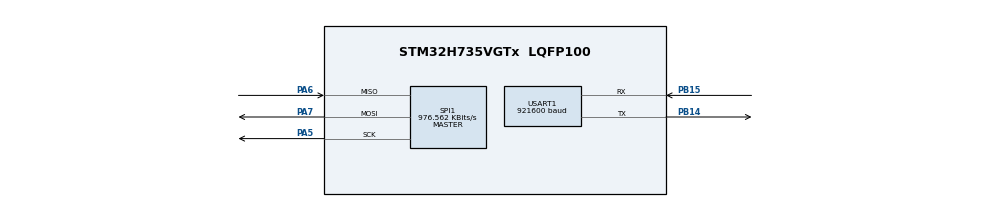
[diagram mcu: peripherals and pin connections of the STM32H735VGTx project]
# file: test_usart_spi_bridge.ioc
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CORTEX_M7.default_mode_Activation=1
Dma.Request0=USART1_RX
Dma.Request1=SPI1_RX
Dma.Request2=SPI1_TX
Dma.Request3=USART1_TX
Dma.SPI1_RX.1.Direction=DMA_PERIPH_TO_MEMORY
Dma.SPI1_RX.1.EventEnable=DISABLE
Dma.SPI1_RX.1.FIFOMode=DMA_FIFOMODE_DISABLE
Dma.SPI1_RX.1.Instance=DMA1_Stream3
Dma.SPI1_RX.1.MemDataAlignment=DMA_MDATAALIGN_BYTE
Dma.SPI1_RX.1.MemInc=DMA_MINC_ENABLE
Dma.SPI1_RX.1.Mode=DMA_CIRCULAR
Dma.SPI1_RX.1.PeriphDataAlignment=DMA_PDATAALIGN_BYTE
Dma.SPI1_RX.1.PeriphInc=DMA_PINC_DISABLE
Dma.SPI1_RX.1.Polarity=HAL_DMAMUX_REQ_GEN_RISING
Dma.SPI1_RX.1.Priority=DMA_PRIORITY_LOW
Dma.SPI1_RX.1.RequestNumber=1
Dma.SPI1_RX.1.SignalID=NONE
Dma.SPI1_RX.1.SyncEnable=DISABLE
Dma.SPI1_RX.1.SyncPolarity=HAL_DMAMUX_SYNC_NO_EVENT
Dma.SPI1_RX.1.SyncRequestNumber=1
Dma.SPI1_RX.1.SyncSignalID=NONE
Dma.SPI1_TX.2.Direction=DMA_MEMORY_TO_PERIPH
Dma.SPI1_TX.2.EventEnable=DISABLE
Dma.SPI1_TX.2.FIFOMode=DMA_FIFOMODE_DISABLE
Dma.SPI1_TX.2.Instance=DMA1_Stream2
Dma.SPI1_TX.2.MemDataAlignment=DMA_MDATAALIGN_BYTE
Dma.SPI1_TX.2.MemInc=DMA_MINC_ENABLE
Dma.SPI1_TX.2.Mode=DMA_NORMAL
Dma.SPI1_TX.2.PeriphDataAlignment=DMA_PDATAALIGN_BYTE
Dma.SPI1_TX.2.PeriphInc=DMA_PINC_DISABLE
Dma.SPI1_TX.2.Polarity=HAL_DMAMUX_REQ_GEN_RISING
Dma.SPI1_TX.2.Priority=DMA_PRIORITY_LOW
Dma.SPI1_TX.2.RequestNumber=1
Dma.SPI1_TX.2.SignalID=NONE
Dma.SPI1_TX.2.SyncEnable=DISABLE
Dma.SPI1_TX.2.SyncPolarity=HAL_DMAMUX_SYNC_NO_EVENT
Dma.SPI1_TX.2.SyncRequestNumber=1
Dma.SPI1_TX.2.SyncSignalID=NONE
Dma.USART1_RX.0.Direction=DMA_PERIPH_TO_MEMORY
Dma.USART1_RX.0.EventEnable=DISABLE
Dma.USART1_RX.0.FIFOMode=DMA_FIFOMODE_DISABLE
Dma.USART1_RX.0.Instance=DMA1_Stream0
Dma.USART1_RX.0.MemDataAlignment=DMA_MDATAALIGN_BYTE
Dma.USART1_RX.0.MemInc=DMA_MINC_ENABLE
Dma.USART1_RX.0.Mode=DMA_CIRCULAR
Dma.USART1_RX.0.PeriphDataAlignment=DMA_PDATAALIGN_BYTE
Dma.USART1_RX.0.PeriphInc=DMA_PINC_DISABLE
Dma.USART1_RX.0.Polarity=HAL_DMAMUX_REQ_GEN_RISING
Dma.USART1_RX.0.Priority=DMA_PRIORITY_LOW
Dma.USART1_RX.0.RequestNumber=1
Dma.USART1_RX.0.SignalID=NONE
Dma.USART1_RX.0.SyncEnable=DISABLE
Dma.USART1_RX.0.SyncPolarity=HAL_DMAMUX_SYNC_NO_EVENT
Dma.USART1_RX.0.SyncRequestNumber=1
Dma.USART1_RX.0.SyncSignalID=NONE
Dma.USART1_TX.3.Direction=DMA_MEMORY_TO_PERIPH
Dma.USART1_TX.3.EventEnable=DISABLE
Dma.USART1_TX.3.FIFOMode=DMA_FIFOMODE_DISABLE
Dma.USART1_TX.3.Instance=DMA1_Stream1
Dma.USART1_TX.3.MemDataAlignment=DMA_MDATAALIGN_BYTE
Dma.USART1_TX.3.MemInc=DMA_MINC_ENABLE
Dma.USART1_TX.3.Mode=DMA_NORMAL
Dma.USART1_TX.3.PeriphDataAlignment=DMA_PDATAALIGN_BYTE
Dma.USART1_TX.3.PeriphInc=DMA_PINC_DISABLE
Dma.USART1_TX.3.Polarity=HAL_DMAMUX_REQ_GEN_RISING
Dma.USART1_TX.3.Priority=DMA_PRIORITY_LOW
Dma.USART1_TX.3.RequestNumber=1
Dma.USART1_TX.3.SignalID=NONE
Dma.USART1_TX.3.SyncEnable=DISABLE
Dma.USART1_TX.3.SyncPolarity=HAL_DMAMUX_SYNC_NO_EVENT
Dma.USART1_TX.3.SyncRequestNumber=1
Dma.USART1_TX.3.SyncSignalID=NONE
FREERTOS.Tasks01=defaultTask,24,128,StartDefaultTask,Default,NULL,Dynamic,NULL,NULL
FREERTOS.configENABLE_BACKWARD_COMPATIBILITY=0
FREERTOS.configMAX_TASK_NAME_LEN=32
FREERTOS.configTOTAL_HEAP_SIZE=131072
FREERTOS.configUSE_NEWLIB_REENTRANT=1
Mcu.Family=STM32H7
Mcu.Name=STM32H735VGTx
Mcu.Package=LQFP100
NVIC.DMA1_Stream0_IRQn=true\:5\:0\:false\:false\:true\:true\:false\:true\:true
NVIC.DMA1_Stream1_IRQn=true\:5\:0\:true\:false\:true\:true\:false\:true\:true
NVIC.DMA1_Stream2_IRQn=true\:5\:0\:true\:false\:true\:true\:false\:true\:true
NVIC.DMA1_Stream3_IRQn=true\:5\:0\:true\:false\:true\:true\:false\:true\:true
NVIC.PriorityGroup=NVIC_PRIORITYGROUP_4
NVIC.SPI1_IRQn=true\:5\:0\:false\:false\:true\:true\:true\:true\:true
NVIC.TIM8_TRG_COM_TIM14_IRQn=true\:15\:0\:false\:false\:true\:false\:false\:true\:true
NVIC.TimeBase=TIM8_TRG_COM_TIM14_IRQn
NVIC.TimeBaseIP=TIM14
NVIC.USART1_IRQn=true\:5\:0\:false\:false\:true\:true\:true\:true\:true
PA13(JTMS/SWDIO).Mode=JTAG_4_pins
PA13(JTMS/SWDIO).Signal=DEBUG_JTMS-SWDIO
PA14(JTCK/SWCLK).Mode=JTAG_4_pins
PA14(JTCK/SWCLK).Signal=DEBUG_JTCK-SWCLK
PA15(JTDI).Mode=JTAG_4_pins
PA15(JTDI).Signal=DEBUG_JTDI
PA5.Mode=Full_Duplex_Master
PA5.Signal=SPI1_SCK
PA6.Mode=Full_Duplex_Master
PA6.Signal=SPI1_MISO
PA7.Mode=Full_Duplex_Master
PA7.Signal=SPI1_MOSI
PB14.Mode=Asynchronous
PB14.Signal=USART1_TX
PB15.Mode=Asynchronous
PB15.Signal=USART1_RX
PB3(JTDO/TRACESWO).Mode=JTAG_4_pins
PB3(JTDO/TRACESWO).Signal=DEBUG_JTDO-SWO
PH0-OSC_IN.Mode=HSE-External-Oscillator
PH0-OSC_IN.Signal=RCC_OSC_IN
PH1-OSC_OUT.Mode=HSE-External-Oscillator
PH1-OSC_OUT.Signal=RCC_OSC_OUT
ProjectManager.HeapSize=0x200
ProjectManager.StackSize=0x400
ProjectManager.TargetToolchain=STM32CubeIDE
RCC.ADCFreq_Value=250000000
RCC.APB1Freq_Value=125000000
RCC.APB2Freq_Value=125000000
RCC.APB3Freq_Value=125000000
RCC.APB4Freq_Value=125000000
RCC.CortexFreq_Value=500000000
RCC.D1PPRE=RCC_APB3_DIV2
RCC.D2PPRE1=RCC_APB1_DIV2
RCC.D2PPRE2=RCC_APB2_DIV2
RCC.D3PPRE=RCC_APB4_DIV2
RCC.DIVM1=5
RCC.DIVM2=5
RCC.DIVM3=5
RCC.DIVN1=100
RCC.DIVN2=100
RCC.DIVN3=100
RCC.DIVP1=1
RCC.DIVQ2=4
RCC.HCLKFreq_Value=250000000
RCC.HPRE=RCC_HCLK_DIV2
RCC.PLLSourceVirtual=RCC_PLLSOURCE_HSE
RCC.SPI123CLockSelection=RCC_SPI123CLKSOURCE_PLL2
RCC.SYSCLKFreq_VALUE=500000000
RCC.SYSCLKSource=RCC_SYSCLKSOURCE_PLLCLK
RCC.USART16CLockSelection=RCC_USART16910CLKSOURCE_PLL2
RCC.USBFreq_Value=250000000
SPI1.BaudRatePrescaler=SPI_BAUDRATEPRESCALER_256
SPI1.CalculateBaudRate=976.562 KBits/s
SPI1.DataSize=SPI_DATASIZE_8BIT
SPI1.Direction=SPI_DIRECTION_2LINES
SPI1.Mode=SPI_MODE_MASTER
SPI1.VirtualType=VM_MASTER
USART1.BaudRate=921600
USART1.VirtualMode-Asynchronous=VM_ASYNC
VP_FREERTOS_VS_CMSIS_V2.Mode=CMSIS_V2
VP_SYS_VS_tim14.Mode=TIM14
board=custom

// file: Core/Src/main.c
/* USER CODE BEGIN Header */
/**
  ******************************************************************************
  * @file           : main.c
  * @brief          : Main program body
  ******************************************************************************
  * @attention
  *
  * Copyright (c) 2024 STMicroelectronics.
  * All rights reserved.
  *
  * This software is licensed under terms that can be found in the LICENSE file
  * in the root directory of this software component.
  * If no LICENSE file comes with this software, it is provided AS-IS.
  *
  ******************************************************************************
  */
/* USER CODE END Header */
#include "main.h"
#include "cmsis_os.h"

/* USER CODE BEGIN Includes */
#include "bridge.h"
/* USER CODE END Includes */

SPI_HandleTypeDef hspi1;
DMA_HandleTypeDef hdma_spi1_rx;
DMA_HandleTypeDef hdma_spi1_tx;

UART_HandleTypeDef huart1;
DMA_HandleTypeDef hdma_usart1_rx;
DMA_HandleTypeDef hdma_usart1_tx;

/* Definitions for defaultTask */
osThreadId_t defaultTaskHandle;
const osThreadAttr_t defaultTask_attributes = {
  .name = "defaultTask",
  .stack_size = 128 * 4,
  .priority = (osPriority_t) osPriorityNormal,
};

void SystemClock_Config(void);
void PeriphCommonClock_Config(void);
static void MPU_Config(void);
static void MX_GPIO_Init(void);
static void MX_DMA_Init(void);
static void MX_USART1_UART_Init(void);
static void MX_SPI1_Init(void);
void StartDefaultTask(void *argument);

int main(void)
{

  /* MPU Configuration--------------------------------------------------------*/
  MPU_Config();

  /* MCU Configuration--------------------------------------------------------*/

  /* Reset of all peripherals, Initializes the Flash interface and the Systick. */
  HAL_Init();

  /* Configure the system clock */
  SystemClock_Config();

/* Configure the peripherals common clocks */
  PeriphCommonClock_Config();

  /* Initialize all configured peripherals */
  MX_GPIO_Init();
  MX_DMA_Init();
  MX_USART1_UART_Init();
  MX_SPI1_Init();

  /* Init scheduler */
  osKernelInitialize();

  /* Create the thread(s) */
  /* creation of defaultTask */
  defaultTaskHandle = osThreadNew(StartDefaultTask, NULL, &defaultTask_attributes);

  /* USER CODE BEGIN RTOS_THREADS */
  /* add threads, ... */
  bridge_enable();
  /* USER CODE END RTOS_THREADS */

  /* Start scheduler */
  osKernelStart();

  /* We should never get here as control is now taken by the scheduler */

  /* Infinite loop */
  while (1)
  {

  }
}

void SystemClock_Config(void)
{
  RCC_OscInitTypeDef RCC_OscInitStruct = {0};
  RCC_ClkInitTypeDef RCC_ClkInitStruct = {0};

  /** Supply configuration update enable
  */
  HAL_PWREx_ConfigSupply(PWR_DIRECT_SMPS_SUPPLY);

  /** Configure the main internal regulator output voltage
  */
  __HAL_PWR_VOLTAGESCALING_CONFIG(PWR_REGULATOR_VOLTAGE_SCALE0);

  while(!__HAL_PWR_GET_FLAG(PWR_FLAG_VOSRDY)) {}

  /** Initializes the RCC Oscillators according to the specified parameters
  * in the RCC_OscInitTypeDef structure.
  */
  RCC_OscInitStruct.OscillatorType = RCC_OSCILLATORTYPE_HSE;
  RCC_OscInitStruct.HSEState = RCC_HSE_ON;
  RCC_OscInitStruct.PLL.PLLState = RCC_PLL_ON;
  RCC_OscInitStruct.PLL.PLLSource = RCC_PLLSOURCE_HSE;
  RCC_OscInitStruct.PLL.PLLM = 5;
  RCC_OscInitStruct.PLL.PLLN = 100;
  RCC_OscInitStruct.PLL.PLLP = 1;
  RCC_OscInitStruct.PLL.PLLQ = 2;
  RCC_OscInitStruct.PLL.PLLR = 2;
  RCC_OscInitStruct.PLL.PLLRGE = RCC_PLL1VCIRANGE_2;
  RCC_OscInitStruct.PLL.PLLVCOSEL = RCC_PLL1VCOWIDE;
  RCC_OscInitStruct.PLL.PLLFRACN = 0;
  if (HAL_RCC_OscConfig(&RCC_OscInitStruct) != HAL_OK)
  {
    Error_Handler();
  }

  /** Initializes the CPU, AHB and APB buses clocks
  */
  RCC_ClkInitStruct.ClockType = RCC_CLOCKTYPE_HCLK|RCC_CLOCKTYPE_SYSCLK
                              |RCC_CLOCKTYPE_PCLK1|RCC_CLOCKTYPE_PCLK2
                              |RCC_CLOCKTYPE_D3PCLK1|RCC_CLOCKTYPE_D1PCLK1;
  RCC_ClkInitStruct.SYSCLKSource = RCC_SYSCLKSOURCE_PLLCLK;
  RCC_ClkInitStruct.SYSCLKDivider = RCC_SYSCLK_DIV1;
  RCC_ClkInitStruct.AHBCLKDivider = RCC_HCLK_DIV2;
  RCC_ClkInitStruct.APB3CLKDivider = RCC_APB3_DIV2;
  RCC_ClkInitStruct.APB1CLKDivider = RCC_APB1_DIV2;
  RCC_ClkInitStruct.APB2CLKDivider = RCC_APB2_DIV2;
  RCC_ClkInitStruct.APB4CLKDivider = RCC_APB4_DIV2;

  if (HAL_RCC_ClockConfig(&RCC_ClkInitStruct, FLASH_LATENCY_3) != HAL_OK)
  {
    Error_Handler();
  }
}

void PeriphCommonClock_Config(void)
{
  RCC_PeriphCLKInitTypeDef PeriphClkInitStruct = {0};

  /** Initializes the peripherals clock
  */
  PeriphClkInitStruct.PeriphClockSelection = RCC_PERIPHCLK_SPI1|RCC_PERIPHCLK_USART1;
  PeriphClkInitStruct.PLL2.PLL2M = 5;
  PeriphClkInitStruct.PLL2.PLL2N = 100;
  PeriphClkInitStruct.PLL2.PLL2P = 2;
  PeriphClkInitStruct.PLL2.PLL2Q = 4;
  PeriphClkInitStruct.PLL2.PLL2R = 2;
  PeriphClkInitStruct.PLL2.PLL2RGE = RCC_PLL2VCIRANGE_2;
  PeriphClkInitStruct.PLL2.PLL2VCOSEL = RCC_PLL2VCOWIDE;
  PeriphClkInitStruct.PLL2.PLL2FRACN = 0;
  PeriphClkInitStruct.Spi123ClockSelection = RCC_SPI123CLKSOURCE_PLL2;
  PeriphClkInitStruct.Usart16ClockSelection = RCC_USART16910CLKSOURCE_PLL2;
  if (HAL_RCCEx_PeriphCLKConfig(&PeriphClkInitStruct) != HAL_OK)
  {
    Error_Handler();
  }
}

static void MX_SPI1_Init(void)
{

  /* SPI1 parameter configuration*/
  hspi1.Instance = SPI1;
  hspi1.Init.Mode = SPI_MODE_MASTER;
  hspi1.Init.Direction = SPI_DIRECTION_2LINES;
  hspi1.Init.DataSize = SPI_DATASIZE_8BIT;
  hspi1.Init.CLKPolarity = SPI_POLARITY_LOW;
  hspi1.Init.CLKPhase = SPI_PHASE_1EDGE;
  hspi1.Init.NSS = SPI_NSS_SOFT;
  hspi1.Init.BaudRatePrescaler = SPI_BAUDRATEPRESCALER_256;
  hspi1.Init.FirstBit = SPI_FIRSTBIT_MSB;
  hspi1.Init.TIMode = SPI_TIMODE_DISABLE;
  hspi1.Init.CRCCalculation = SPI_CRCCALCULATION_DISABLE;
  hspi1.Init.CRCPolynomial = 0x0;
  hspi1.Init.NSSPMode = SPI_NSS_PULSE_ENABLE;
  hspi1.Init.NSSPolarity = SPI_NSS_POLARITY_LOW;
  hspi1.Init.FifoThreshold = SPI_FIFO_THRESHOLD_01DATA;
  hspi1.Init.TxCRCInitializationPattern = SPI_CRC_INITIALIZATION_ALL_ZERO_PATTERN;
  hspi1.Init.RxCRCInitializationPattern = SPI_CRC_INITIALIZATION_ALL_ZERO_PATTERN;
  hspi1.Init.MasterSSIdleness = SPI_MASTER_SS_IDLENESS_00CYCLE;
  hspi1.Init.MasterInterDataIdleness = SPI_MASTER_INTERDATA_IDLENESS_00CYCLE;
  hspi1.Init.MasterReceiverAutoSusp = SPI_MASTER_RX_AUTOSUSP_DISABLE;
  hspi1.Init.MasterKeepIOState = SPI_MASTER_KEEP_IO_STATE_DISABLE;
  hspi1.Init.IOSwap = SPI_IO_SWAP_DISABLE;
  if (HAL_SPI_Init(&hspi1) != HAL_OK)
  {
    Error_Handler();
  }

}

static void MX_USART1_UART_Init(void)
{

  huart1.Instance = USART1;
  huart1.Init.BaudRate = 921600;
  huart1.Init.WordLength = UART_WORDLENGTH_8B;
  huart1.Init.StopBits = UART_STOPBITS_1;
  huart1.Init.Parity = UART_PARITY_NONE;
  huart1.Init.Mode = UART_MODE_TX_RX;
  huart1.Init.HwFlowCtl = UART_HWCONTROL_NONE;
  huart1.Init.OverSampling = UART_OVERSAMPLING_16;
  huart1.Init.OneBitSampling = UART_ONE_BIT_SAMPLE_DISABLE;
  huart1.Init.ClockPrescaler = UART_PRESCALER_DIV1;
  huart1.AdvancedInit.AdvFeatureInit = UART_ADVFEATURE_NO_INIT;
  if (HAL_UART_Init(&huart1) != HAL_OK)
  {
    Error_Handler();
  }
  if (HAL_UARTEx_SetTxFifoThreshold(&huart1, UART_TXFIFO_THRESHOLD_1_8) != HAL_OK)
  {
    Error_Handler();
  }
  if (HAL_UARTEx_SetRxFifoThreshold(&huart1, UART_RXFIFO_THRESHOLD_1_8) != HAL_OK)
  {
    Error_Handler();
  }
  if (HAL_UARTEx_DisableFifoMode(&huart1) != HAL_OK)
  {
    Error_Handler();
  }

}

static void MX_DMA_Init(void)
{

  /* DMA controller clock enable */
  __HAL_RCC_DMA1_CLK_ENABLE();

  /* DMA interrupt init */
  /* DMA1_Stream0_IRQn interrupt configuration */
  HAL_NVIC_SetPriority(DMA1_Stream0_IRQn, 5, 0);
  HAL_NVIC_EnableIRQ(DMA1_Stream0_IRQn);
  /* DMA1_Stream1_IRQn interrupt configuration */
  HAL_NVIC_SetPriority(DMA1_Stream1_IRQn, 5, 0);
  HAL_NVIC_EnableIRQ(DMA1_Stream1_IRQn);
  /* DMA1_Stream2_IRQn interrupt configuration */
  HAL_NVIC_SetPriority(DMA1_Stream2_IRQn, 5, 0);
  HAL_NVIC_EnableIRQ(DMA1_Stream2_IRQn);
  /* DMA1_Stream3_IRQn interrupt configuration */
  HAL_NVIC_SetPriority(DMA1_Stream3_IRQn, 5, 0);
  HAL_NVIC_EnableIRQ(DMA1_Stream3_IRQn);

}

static void MX_GPIO_Init(void)
{

  /* GPIO Ports Clock Enable */
  __HAL_RCC_GPIOH_CLK_ENABLE();
  __HAL_RCC_GPIOA_CLK_ENABLE();
  __HAL_RCC_GPIOB_CLK_ENABLE();

}

void StartDefaultTask(void *argument)
{
  /* USER CODE BEGIN 5 */
  /* Infinite loop */
  for(;;)
  {
    osDelay(100UL);
  }
  /* USER CODE END 5 */
}

 /* MPU Configuration */

void MPU_Config(void)
{
  MPU_Region_InitTypeDef MPU_InitStruct = {0};

  /* Disables the MPU */
  HAL_MPU_Disable();

  /** Initializes and configures the Region and the memory to be protected
  */
  MPU_InitStruct.Enable = MPU_REGION_ENABLE;
  MPU_InitStruct.Number = MPU_REGION_NUMBER0;
  MPU_InitStruct.BaseAddress = 0x0;
  MPU_InitStruct.Size = MPU_REGION_SIZE_4GB;
  MPU_InitStruct.SubRegionDisable = 0x87;
  MPU_InitStruct.TypeExtField = MPU_TEX_LEVEL0;
  MPU_InitStruct.AccessPermission = MPU_REGION_NO_ACCESS;
  MPU_InitStruct.DisableExec = MPU_INSTRUCTION_ACCESS_DISABLE;
  MPU_InitStruct.IsShareable = MPU_ACCESS_SHAREABLE;
  MPU_InitStruct.IsCacheable = MPU_ACCESS_NOT_CACHEABLE;
  MPU_InitStruct.IsBufferable = MPU_ACCESS_NOT_BUFFERABLE;

  HAL_MPU_ConfigRegion(&MPU_InitStruct);
  /* Enables the MPU */
  HAL_MPU_Enable(MPU_PRIVILEGED_DEFAULT);

}

void HAL_TIM_PeriodElapsedCallback(TIM_HandleTypeDef *htim)
{
  if (htim->Instance == TIM14) {
    HAL_IncTick();
  }
}

void Error_Handler(void)
{
  __disable_irq();
  while (1)
  {
  }
}
